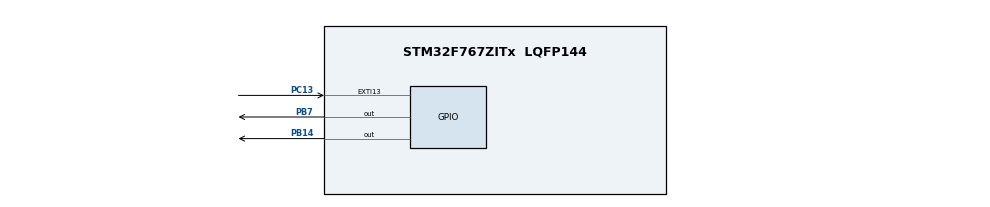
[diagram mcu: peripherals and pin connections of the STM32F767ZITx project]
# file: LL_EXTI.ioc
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CORTEX_M7.default_mode_Activation=1
Mcu.Family=STM32F7
Mcu.Name=STM32F767ZITx
Mcu.Package=LQFP144
NVIC.EXTI15_10_IRQn=true\:0\:0\:false\:true\:true\:1\:true\:true\:true
NVIC.PriorityGroup=NVIC_PRIORITYGROUP_4
PB14.Signal=GPIO_Output
PB7.Signal=GPIO_Output
PC13.Signal=GPXTI13
ProjectManager.HeapSize=0x200
ProjectManager.StackSize=0x400
ProjectManager.TargetToolchain=STM32CubeIDE
RCC.HSE_VALUE=25000000
RCC.HSI_VALUE=16000000
RCC.LSE_VALUE=32768
RCC.USBFreq_Value=96000000
RCC.VCOOutputFreq_Value=192000000
board=custom

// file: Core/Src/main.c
/* USER CODE BEGIN Header */
/**
  ******************************************************************************
  * @file           : main.c
  * @brief          : Main program body
  ******************************************************************************
  * @attention
  *
  * Copyright (c) 2026 STMicroelectronics.
  * All rights reserved.
  *
  * This software is licensed under terms that can be found in the LICENSE file
  * in the root directory of this software component.
  * If no LICENSE file comes with this software, it is provided AS-IS.
  *
  ******************************************************************************
  */
/* USER CODE END Header */
#include "main.h"
#include "gpio.h"

/* USER CODE BEGIN Includes */
#include "stm32f7xx_it.h"
/* USER CODE END Includes */

/* USER CODE BEGIN PV */
volatile uint8_t exti_triggered;

volatile uint32_t currentTime;

#define period 2000

/* USER CODE END PV */

void SystemClock_Config(void);
static void MPU_Config(void);
static void MX_NVIC_Init(void);

int main(void)
{

  /* MPU Configuration--------------------------------------------------------*/
  MPU_Config();

  /* MCU Configuration--------------------------------------------------------*/

  /* Reset of all peripherals, Initializes the Flash interface and the Systick. */
  LL_APB1_GRP1_EnableClock(LL_APB1_GRP1_PERIPH_PWR);
  LL_APB2_GRP1_EnableClock(LL_APB2_GRP1_PERIPH_SYSCFG);

  /* System interrupt init*/
  NVIC_SetPriorityGrouping(NVIC_PRIORITYGROUP_4);

  /* SysTick_IRQn interrupt configuration */
  NVIC_SetPriority(SysTick_IRQn, NVIC_EncodePriority(NVIC_GetPriorityGrouping(),15, 0));

  /* Configure the system clock */
  SystemClock_Config();

  /* Initialize all configured peripherals */
  MX_GPIO_Init();

  /* Initialize interrupts */
  MX_NVIC_Init();
  /* USER CODE BEGIN 2 */
  SysTick->CTRL|=SysTick_CTRL_TICKINT_Msk;
  /* USER CODE END 2 */

  /* Infinite loop */
  /* USER CODE BEGIN WHILE */
  while (1)
  {
	 if((getCurrentTicks()-currentTime>period)&&exti_triggered==1)
	 {
		 LL_GPIO_ResetOutputPin(GPIOB, LL_GPIO_PIN_7);
		 exti_triggered=0;

	 }

	 if(getCurrentTicks()%500==0)
	 {
		 LL_GPIO_TogglePin(GPIOB, LL_GPIO_PIN_14);
	 }
    /* USER CODE END WHILE */

  }
}

void SystemClock_Config(void)
{
  LL_FLASH_SetLatency(LL_FLASH_LATENCY_0);
  while(LL_FLASH_GetLatency()!= LL_FLASH_LATENCY_0)
  {
  }
  LL_PWR_SetRegulVoltageScaling(LL_PWR_REGU_VOLTAGE_SCALE3);
  LL_PWR_DisableOverDriveMode();
  LL_RCC_HSI_SetCalibTrimming(16);
  LL_RCC_HSI_Enable();

   /* Wait till HSI is ready */
  while(LL_RCC_HSI_IsReady() != 1)
  {

  }
  LL_RCC_SetAHBPrescaler(LL_RCC_SYSCLK_DIV_1);
  LL_RCC_SetAPB1Prescaler(LL_RCC_APB1_DIV_1);
  LL_RCC_SetAPB2Prescaler(LL_RCC_APB2_DIV_1);
  LL_RCC_SetSysClkSource(LL_RCC_SYS_CLKSOURCE_HSI);

   /* Wait till System clock is ready */
  while(LL_RCC_GetSysClkSource() != LL_RCC_SYS_CLKSOURCE_STATUS_HSI)
  {

  }
  LL_Init1msTick(16000000);
  LL_SetSystemCoreClock(16000000);

   /* Set Timers Clock Prescalers */
  LL_RCC_SetTIMPrescaler(LL_RCC_TIM_PRESCALER_TWICE);
}

/**
  * @brief NVIC Configuration.
  * @retval None
  */
static void MX_NVIC_Init(void)
{
  /* EXTI15_10_IRQn interrupt configuration */
  NVIC_SetPriority(EXTI15_10_IRQn, NVIC_EncodePriority(NVIC_GetPriorityGrouping(),0, 0));
  NVIC_EnableIRQ(EXTI15_10_IRQn);
}

 /* MPU Configuration */

void MPU_Config(void)
{

  /* Disables the MPU */
  LL_MPU_Disable();

  /** Initializes and configures the Region and the memory to be protected
  */
  LL_MPU_ConfigRegion(LL_MPU_REGION_NUMBER0, 0x87, 0x0, LL_MPU_REGION_SIZE_4GB|LL_MPU_TEX_LEVEL0|LL_MPU_REGION_NO_ACCESS|LL_MPU_INSTRUCTION_ACCESS_DISABLE|LL_MPU_ACCESS_SHAREABLE|LL_MPU_ACCESS_NOT_CACHEABLE|LL_MPU_ACCESS_NOT_BUFFERABLE);
  /* Enables the MPU */
  LL_MPU_Enable(LL_MPU_CTRL_PRIVILEGED_DEFAULT);

}

void Error_Handler(void)
{
  __disable_irq();
  while (1)
  {
  }
}
